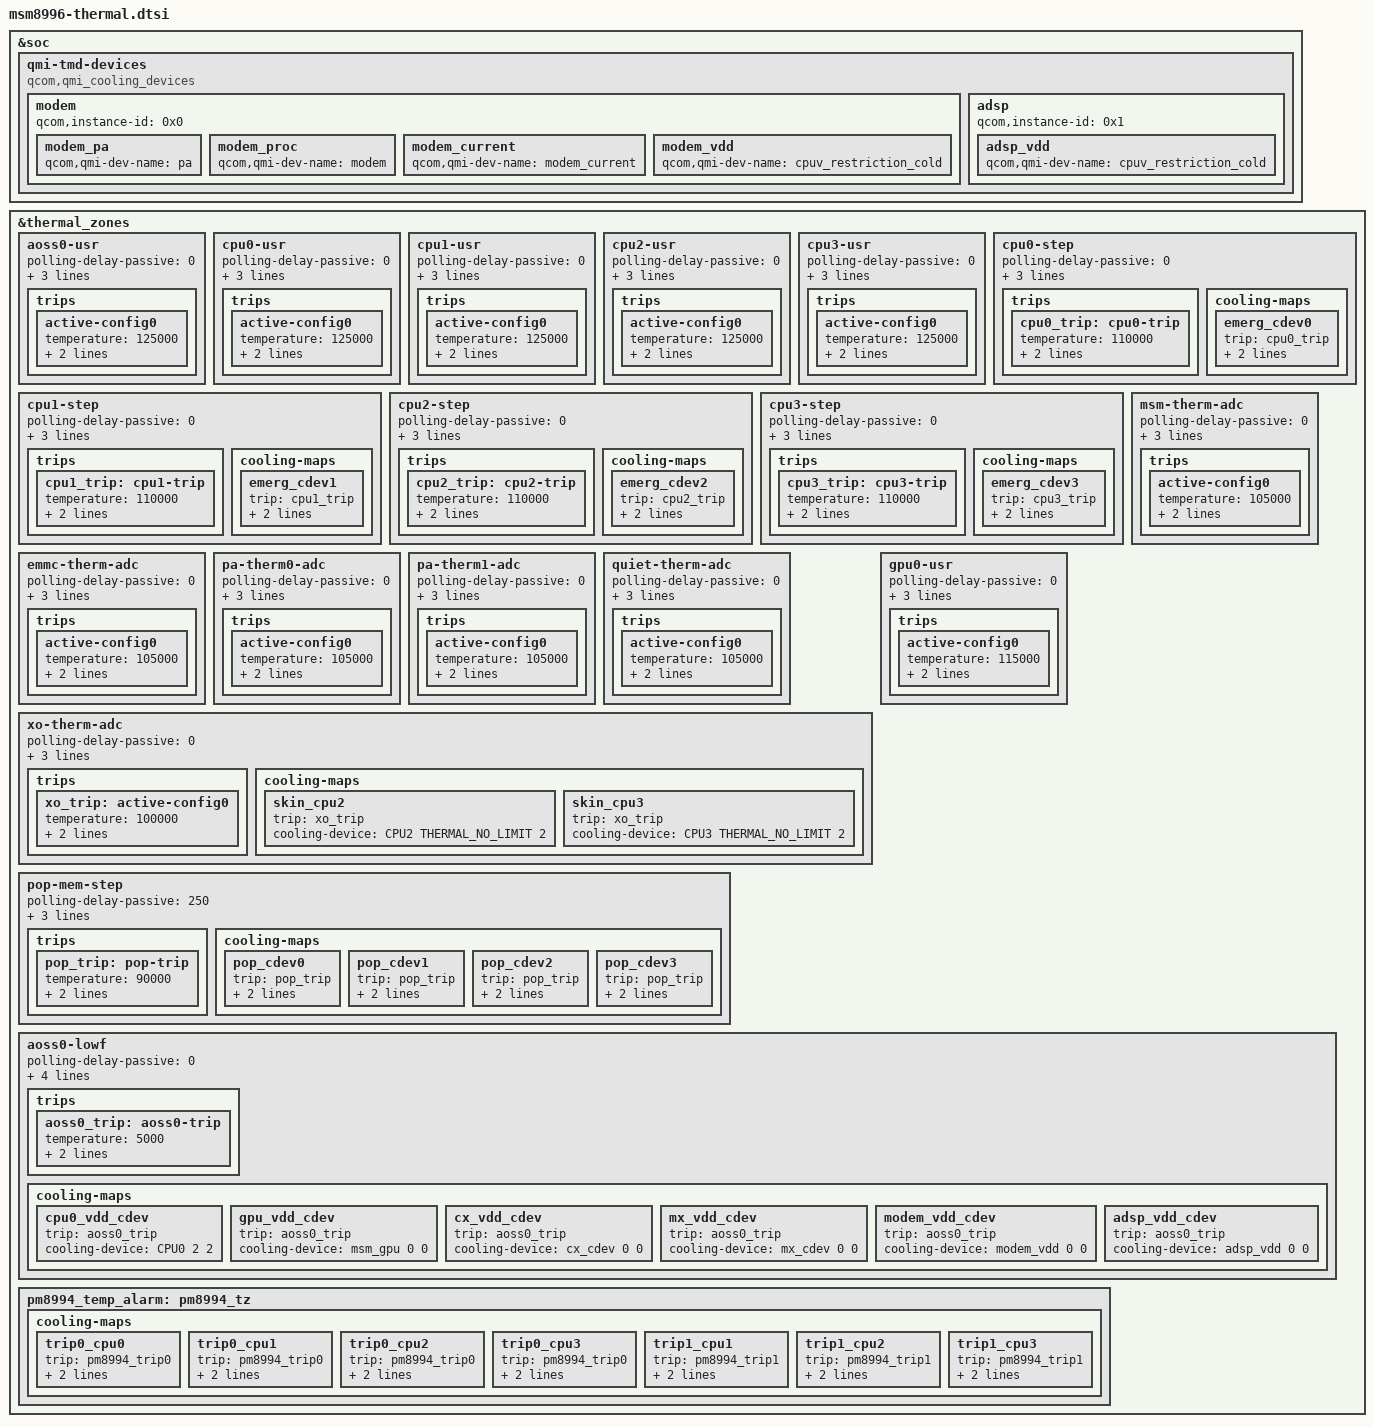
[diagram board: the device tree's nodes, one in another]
#include <dt-bindings/thermal/thermal.h>

&soc {
	qmi-tmd-devices {
		compatible = "qcom,qmi_cooling_devices";

		modem {
			qcom,instance-id = <0x0>;

			modem_pa: modem_pa {
				qcom,qmi-dev-name = "pa";
				#cooling-cells = <2>;
			};

			modem_proc: modem_proc {
				qcom,qmi-dev-name = "modem";
				#cooling-cells = <2>;
			};

			modem_current: modem_current {
				qcom,qmi-dev-name = "modem_current";
				#cooling-cells = <2>;
			};

			modem_vdd: modem_vdd {
				qcom,qmi-dev-name = "cpuv_restriction_cold";
				#cooling-cells = <2>;
			};
		};

		adsp {
			qcom,instance-id = <0x1>;

			adsp_vdd: adsp_vdd {
				qcom,qmi-dev-name = "cpuv_restriction_cold";
				#cooling-cells = <2>;
			};
		};
	};
};

&thermal_zones {
	aoss0-usr {
		polling-delay-passive = <0>;
		polling-delay = <0>;
		thermal-governor = "user_space";
		thermal-sensors = <&tsens0 0>;
		trips {
			active-config0 {
				temperature = <125000>;
				hysteresis = <1000>;
				type = "passive";
			};
		};
	};

	cpu0-usr {
		polling-delay-passive = <0>;
		polling-delay = <0>;
		thermal-governor = "user_space";
		thermal-sensors = <&tsens0 4>;
		trips {
			active-config0 {
				temperature = <125000>;
				hysteresis = <1000>;
				type = "passive";
			};
		};
	};

	cpu1-usr {
		polling-delay-passive = <0>;
		polling-delay = <0>;
		thermal-governor = "user_space";
		thermal-sensors = <&tsens0 6>;
		trips {
			active-config0 {
				temperature = <125000>;
				hysteresis = <1000>;
				type = "passive";
			};
		};
	};

	cpu2-usr {
		polling-delay-passive = <0>;
		polling-delay = <0>;
		thermal-governor = "user_space";
		thermal-sensors = <&tsens0 9>;
		trips {
			active-config0 {
				temperature = <125000>;
				hysteresis = <1000>;
				type = "passive";
			};
		};
	};

	cpu3-usr {
		polling-delay-passive = <0>;
		polling-delay = <0>;
		thermal-sensors = <&tsens0 11>;
		thermal-governor = "user_space";
		trips {
			active-config0 {
				temperature = <125000>;
				hysteresis = <1000>;
				type = "passive";
			};
		};
	};

	cpu0-step {
		polling-delay-passive = <0>;
		polling-delay = <0>;
		thermal-governor = "user_space";
		thermal-sensors = <&tsens0 4>;
		trips {
			cpu0_trip: cpu0-trip {
				temperature = <110000>;
				hysteresis = <10000>;
				type = "passive";
			};
		};
		cooling-maps {
			emerg_cdev0 {
				trip = <&cpu0_trip>;
				cooling-device =
					<&CPU0 THERMAL_MAX_LIMIT
						THERMAL_MAX_LIMIT>;
			};
		};
	};

	cpu1-step {
		polling-delay-passive = <0>;
		polling-delay = <0>;
		thermal-governor = "user_space";
		thermal-sensors = <&tsens0 6>;
		trips {
			cpu1_trip: cpu1-trip {
				temperature = <110000>;
				hysteresis = <10000>;
				type = "passive";
			};
		};
		cooling-maps {
			emerg_cdev1 {
				trip = <&cpu1_trip>;
				cooling-device =
					<&CPU1 THERMAL_MAX_LIMIT
						THERMAL_MAX_LIMIT>;
			};
		};
	};

	cpu2-step {
		polling-delay-passive = <0>;
		polling-delay = <0>;
		thermal-governor = "user_space";
		thermal-sensors = <&tsens0 9>;
		trips {
			cpu2_trip: cpu2-trip {
				temperature = <110000>;
				hysteresis = <10000>;
				type = "passive";
			};
		};
		cooling-maps {
			emerg_cdev2 {
				trip = <&cpu2_trip>;
				cooling-device =
					<&CPU2 THERMAL_MAX_LIMIT
						THERMAL_MAX_LIMIT>;
			};
		};
	};

	cpu3-step {
		polling-delay-passive = <0>;
		polling-delay = <0>;
		thermal-sensors = <&tsens0 11>;
		thermal-governor = "user_space";
		trips {
			cpu3_trip: cpu3-trip {
				temperature = <110000>;
				hysteresis = <10000>;
				type = "passive";
			};
		};
		cooling-maps {
			emerg_cdev3 {
				trip = <&cpu3_trip>;
				cooling-device =
					<&CPU3 THERMAL_MAX_LIMIT
						THERMAL_MAX_LIMIT>;
			};
		};
	};

	msm-therm-adc {
		polling-delay-passive = <0>;
		polling-delay = <0>;
		thermal-sensors = <&pm8994_adc_tm 0x73>;
		thermal-governor = "user_space";

		trips {
			active-config0 {
				temperature = <105000>;
				hysteresis = <10000>;
				type = "passive";
			};
		};
	};

	emmc-therm-adc {
		polling-delay-passive = <0>;
		polling-delay = <0>;
		thermal-sensors = <&pm8994_adc_tm 0x74>;
		thermal-governor = "user_space";

		trips {
			active-config0 {
				temperature = <105000>;
				hysteresis = <1000>;
				type = "passive";
			};
		};
	};

	pa-therm0-adc {
		polling-delay-passive = <0>;
		polling-delay = <0>;
		thermal-sensors = <&pm8994_adc_tm 0x75>;
		thermal-governor = "user_space";

		trips {
			active-config0 {
				temperature = <105000>;
				hysteresis = <10000>;
				type = "passive";
			};
		};
	};

	pa-therm1-adc {
		polling-delay-passive = <0>;
		polling-delay = <0>;
		thermal-sensors = <&pm8994_adc_tm 0x77>;
		thermal-governor = "user_space";

		trips {
			active-config0 {
				temperature = <105000>;
				hysteresis = <10000>;
				type = "passive";
			};
		};
	};

	quiet-therm-adc {
		polling-delay-passive = <0>;
		polling-delay = <0>;
		thermal-sensors = <&pm8994_adc_tm 0x78>;
		thermal-governor = "user_space";

		trips {
			active-config0 {
				temperature = <105000>;
				hysteresis = <10000>;
				type = "passive";
			};
		};
	};

	xo-therm-adc {
		polling-delay-passive = <0>;
		polling-delay = <0>;
		thermal-sensors = <&pm8994_adc_tm 0x7c>;
		thermal-governor = "user_space";

		trips {
			xo_trip: active-config0 {
				temperature = <100000>;
				hysteresis = <10000>;
				type = "passive";
			};
		};
		cooling-maps {
			skin_cpu2 {
				trip = <&xo_trip>;
				cooling-device = <&CPU2 THERMAL_NO_LIMIT 2>;
			};
			skin_cpu3 {
				trip = <&xo_trip>;
				cooling-device = <&CPU3 THERMAL_NO_LIMIT 2>;
			};
		};
	};

	gpu0-usr {
		polling-delay-passive = <0>;
		polling-delay = <0>;
		thermal-sensors = <&tsens0 15>;
		thermal-governor = "user_space";
		trips {
			active-config0 {
				temperature = <115000>;
				hysteresis = <10000>;
				type = "passive";
			};
		};
	};

	pop-mem-step {
		polling-delay-passive = <250>;
		polling-delay = <0>;
		thermal-sensors = <&tsens0 2>;
		thermal-governor = "step_wise";
		trips {
			pop_trip: pop-trip {
				temperature = <90000>;
				hysteresis = <0>;
				type = "passive";
			};
		};
		cooling-maps {
			pop_cdev0 {
				trip = <&pop_trip>;
				cooling-device =
					<&CPU0 THERMAL_NO_LIMIT
						(THERMAL_MAX_LIMIT-1)>;
			};
			pop_cdev1 {
				trip = <&pop_trip>;
				cooling-device =
					<&CPU1 THERMAL_NO_LIMIT
						(THERMAL_MAX_LIMIT-1)>;
			};
			pop_cdev2 {
				trip = <&pop_trip>;
				cooling-device =
					<&CPU2 THERMAL_NO_LIMIT
						(THERMAL_MAX_LIMIT-1)>;
			};
			pop_cdev3 {
				trip = <&pop_trip>;
				cooling-device =
					<&CPU3 THERMAL_NO_LIMIT
						(THERMAL_MAX_LIMIT-1)>;
			};
		};
	};

	aoss0-lowf {
		polling-delay-passive = <0>;
		polling-delay = <0>;
		thermal-governor = "low_limits_floor";
		thermal-sensors = <&tsens0 0>;
		tracks-low;
		trips {
			aoss0_trip: aoss0-trip {
				temperature = <5000>;
				hysteresis = <5000>;
				type = "passive";
			};
		};
		cooling-maps {
			cpu0_vdd_cdev {
				trip = <&aoss0_trip>;
				cooling-device = <&CPU0 2 2>;
			};
			gpu_vdd_cdev {
				trip = <&aoss0_trip>;
				cooling-device = <&msm_gpu 0 0>;
			};
			cx_vdd_cdev {
				trip = <&aoss0_trip>;
				cooling-device = <&cx_cdev 0 0>;
			};
			mx_vdd_cdev {
				trip = <&aoss0_trip>;
				cooling-device = <&mx_cdev 0 0>;
			};
			modem_vdd_cdev {
				trip = <&aoss0_trip>;
				cooling-device = <&modem_vdd 0 0>;
			};
			adsp_vdd_cdev {
				trip = <&aoss0_trip>;
				cooling-device = <&adsp_vdd 0 0>;
			};
		};
	};

	pm8994_temp_alarm: pm8994_tz {
		cooling-maps {
			trip0_cpu0 {
				trip = <&pm8994_trip0>;
				cooling-device =
					<&CPU0 (THERMAL_MAX_LIMIT-1)
						(THERMAL_MAX_LIMIT-1)>;
			};
			trip0_cpu1 {
				trip = <&pm8994_trip0>;
				cooling-device =
					<&CPU1 (THERMAL_MAX_LIMIT-1)
						(THERMAL_MAX_LIMIT-1)>;
			};
			trip0_cpu2 {
				trip = <&pm8994_trip0>;
				cooling-device =
					<&CPU2 (THERMAL_MAX_LIMIT-1)
						(THERMAL_MAX_LIMIT-1)>;
			};
			trip0_cpu3 {
				trip = <&pm8994_trip0>;
				cooling-device =
					<&CPU3 (THERMAL_MAX_LIMIT-1)
						(THERMAL_MAX_LIMIT-1)>;
			};
			trip1_cpu1 {
				trip = <&pm8994_trip1>;
				cooling-device =
					<&CPU1 THERMAL_MAX_LIMIT
						THERMAL_MAX_LIMIT>;
			};
			trip1_cpu2 {
				trip = <&pm8994_trip1>;
				cooling-device =
					<&CPU2 THERMAL_MAX_LIMIT
						THERMAL_MAX_LIMIT>;
			};
			trip1_cpu3 {
				trip = <&pm8994_trip1>;
				cooling-device =
					<&CPU3 THERMAL_MAX_LIMIT
						THERMAL_MAX_LIMIT>;
			};
		};
	};
};


